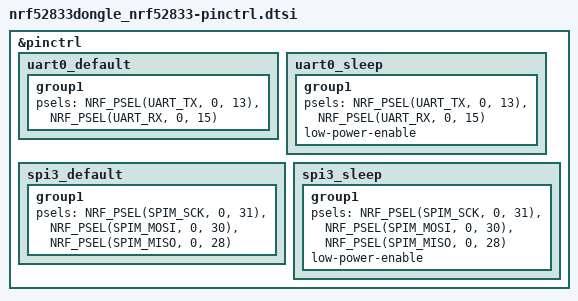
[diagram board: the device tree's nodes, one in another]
/*
 * Copyright (c) 2024 K4W UWB Tag
 * SPDX-License-Identifier: Apache-2.0
 */

&pinctrl {
	uart0_default: uart0_default {
		group1 {
			psels = <NRF_PSEL(UART_TX, 0, 13)>,
				<NRF_PSEL(UART_RX, 0, 15)>;
		};
	};

	uart0_sleep: uart0_sleep {
		group1 {
			psels = <NRF_PSEL(UART_TX, 0, 13)>,
				<NRF_PSEL(UART_RX, 0, 15)>;
			low-power-enable;
		};
	};

	spi3_default: spi3_default {
		group1 {
			psels = <NRF_PSEL(SPIM_SCK, 0, 31)>,
				<NRF_PSEL(SPIM_MOSI, 0, 30)>,
				<NRF_PSEL(SPIM_MISO, 0, 28)>;
		};
	};

	spi3_sleep: spi3_sleep {
		group1 {
			psels = <NRF_PSEL(SPIM_SCK, 0, 31)>,
				<NRF_PSEL(SPIM_MOSI, 0, 30)>,
				<NRF_PSEL(SPIM_MISO, 0, 28)>;
			low-power-enable;
		};
	};
};
